AUTOSAR XML (schema 00048)
package /COM/VECTOR/CFG/WORKFLOW/SYSDESC/SYNC
  system SYSTEM: category=ECU_EXTRACT
    system mapping MAPPINGS
      data-mappings:
        data-element=COMPOSITIONTYPE.Sig_Light_1_Ctrl.Sig_Light_1_Ctrl, system-signal=Sig_Light_1_Ctrl
        data-element=COMPOSITIONTYPE.Sig_Light_1_Sts.Sig_Light_1_Sts, system-signal=Sig_Light_1_Sts
    root-software-compositions:
      root sw composition prototype COMPOSITIONTYPE: flat-map=FLATMAP, software-composition=COMPOSITIONTYPE
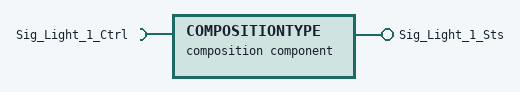
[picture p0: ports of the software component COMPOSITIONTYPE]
  composition sw component type COMPOSITIONTYPE  # UB:Derived from original system description
    require port Sig_Light_1_Ctrl: nonqueued-receiver-com-spec{data-element=Sig_Light_1_Ctrl, init-value=0}, required-interface=Sig_Light_1_Ctrl
    provide port Sig_Light_1_Sts: nonqueued-sender-com-spec{data-element=Sig_Light_1_Sts, init-value=0}, provided-interface=Sig_Light_1_Sts
    6 x component:
      BswM: type=BswM
      ComM: type=ComM
      Det: type=Det
      EcuM: type=EcuM
      Os_OsCore0_swc: type=Os_OsCore0_swc
      ECU_APPM: type=ECU_APPM
    connect BswM.Switch_ESH_ModeSwitch -> BswM.Notification_ESH_ModeNotification
    delegate ECU_APPM.Sig_Light_1_Ctrl <-> outer port Sig_Light_1_Ctrl  # UB:Derived from original system description
    delegate ECU_APPM.Sig_Light_1_Sts <-> outer port Sig_Light_1_Sts  # UB:Derived from original system description
    connect ComM.UR_CN_N_CAN1_e2dd2bfb -> ECU_APPM.UR_CN_N_CAN1_e2dd2bfb
  end to end protection set E2EPROTECTIONSET
  port interface mapping set PORTINTERFACEMAPPINGSET
